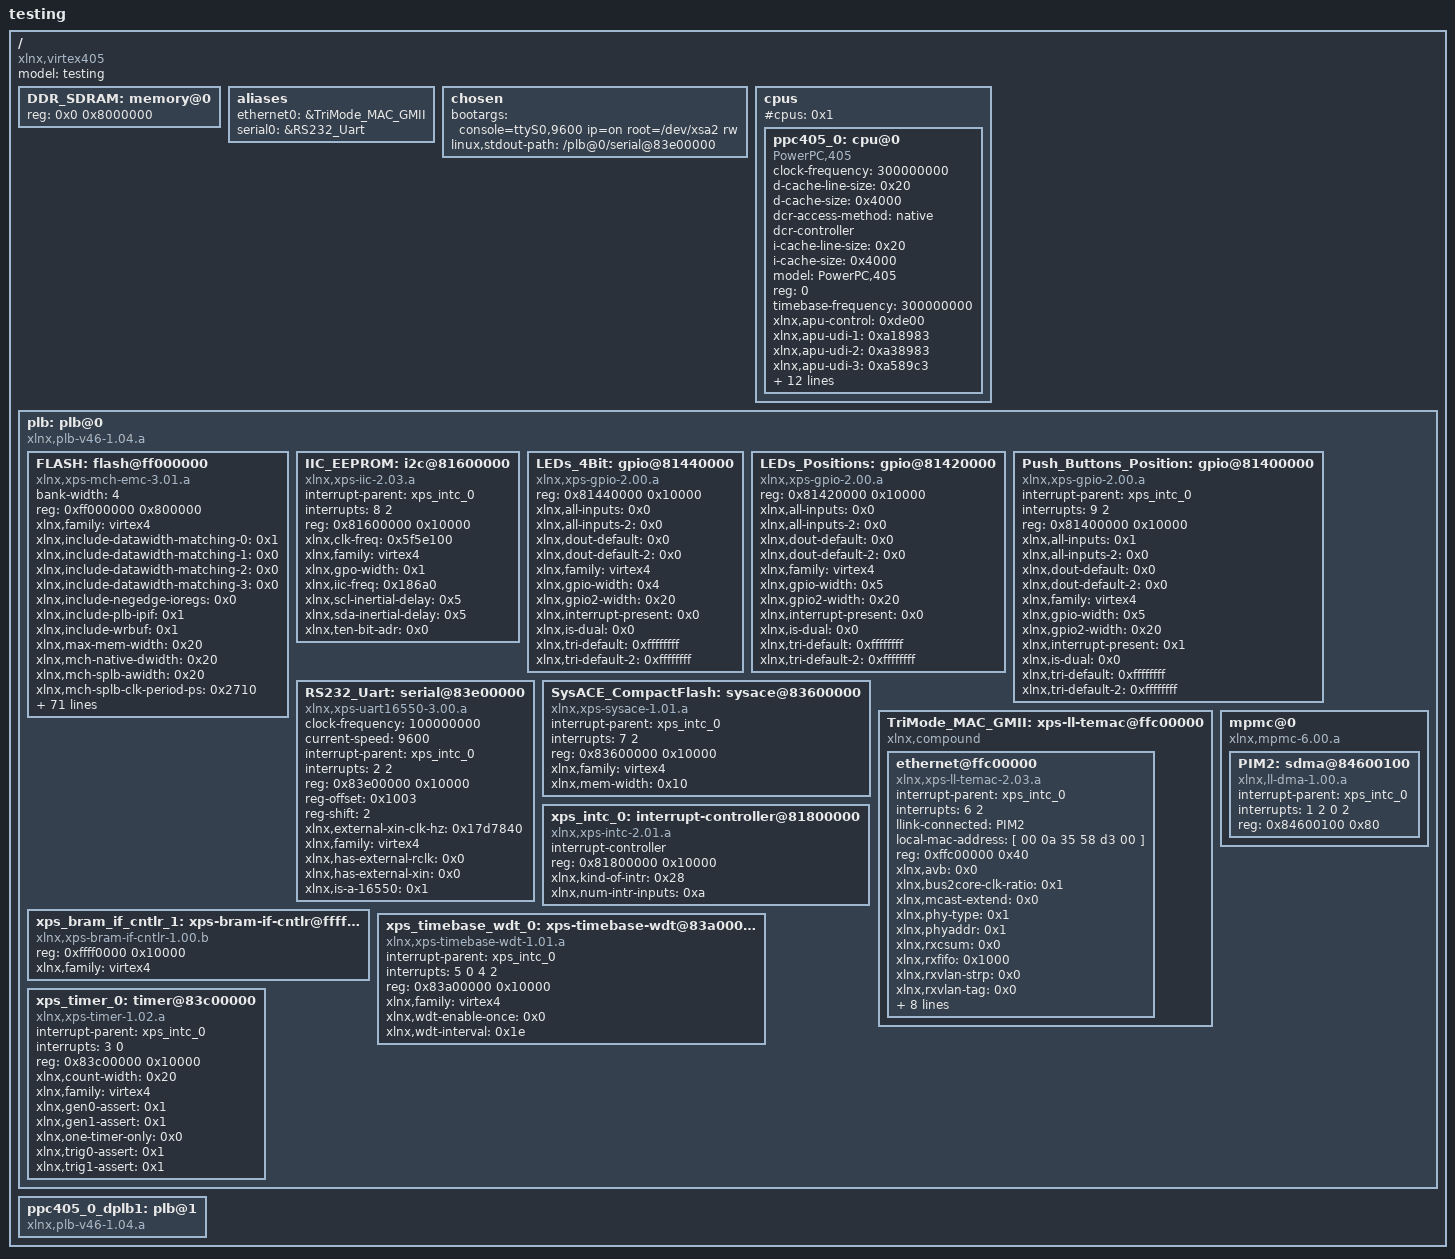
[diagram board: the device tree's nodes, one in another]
/*
 * Device Tree Generator version: 1.3
 *
 * (C) Copyright 2007-2008 Xilinx, Inc.
 * (C) Copyright 2007-2009 Michal Simek
 *
 * Michal SIMEK <monstr@monstr.eu>
 *
 * This program is free software; you can redistribute it and/or
 * modify it under the terms of the GNU General Public License as
 * published by the Free Software Foundation; either version 2 of
 * the License, or (at your option) any later version.
 *
 * This program is distributed in the hope that it will be useful,
 * but WITHOUT ANY WARRANTY; without even the implied warranty of
 * MERCHANTABILITY or FITNESS FOR A PARTICULAR PURPOSE. See the
 * GNU General Public License for more details.
 *
 * You should have received a copy of the GNU General Public License
 * along with this program; if not, write to the Free Software
 * Foundation, Inc., 59 Temple Place, Suite 330, Boston,
 * MA 02111-1307 USA
 *
 * CAUTION: This file is automatically generated by libgen.
 * Version: Xilinx EDK 12.1 EDK_MS1.53d
 *
 * XPS project directory: xilinx-ml405-ref
 */

/dts-v1/;
/ {
	#address-cells = <1>;
	#size-cells = <1>;
	compatible = "xlnx,virtex405", "xlnx,virtex";
	model = "testing";
	DDR_SDRAM: memory@0 {
		device_type = "memory";
		reg = < 0x0 0x8000000 >;
	} ;
	aliases {
		ethernet0 = &TriMode_MAC_GMII;
		serial0 = &RS232_Uart;
	} ;
	chosen {
		bootargs = "console=ttyS0,9600 ip=on root=/dev/xsa2 rw";
		linux,stdout-path = "/plb@0/serial@83e00000";
	} ;
	cpus {
		#address-cells = <1>;
		#cpus = <0x1>;
		#size-cells = <0>;
		ppc405_0: cpu@0 {
			clock-frequency = <300000000>;
			compatible = "PowerPC,405", "ibm,ppc405";
			d-cache-line-size = <0x20>;
			d-cache-size = <0x4000>;
			dcr-access-method = "native";
			dcr-controller ;
			device_type = "cpu";
			i-cache-line-size = <0x20>;
			i-cache-size = <0x4000>;
			model = "PowerPC,405";
			reg = <0>;
			timebase-frequency = <300000000>;
			xlnx,apu-control = <0xde00>;
			xlnx,apu-udi-1 = <0xa18983>;
			xlnx,apu-udi-2 = <0xa38983>;
			xlnx,apu-udi-3 = <0xa589c3>;
			xlnx,apu-udi-4 = <0xa789c3>;
			xlnx,apu-udi-5 = <0xa98c03>;
			xlnx,apu-udi-6 = <0xab8c03>;
			xlnx,apu-udi-7 = <0xad8c43>;
			xlnx,apu-udi-8 = <0xaf8c43>;
			xlnx,deterministic-mult = <0x0>;
			xlnx,disable-operand-forwarding = <0x1>;
			xlnx,fastest-plb-clock = "DPLB0";
			xlnx,generate-plb-timespecs = <0x1>;
			xlnx,mmu-enable = <0x1>;
			xlnx,pvr-high = <0x0>;
			xlnx,pvr-low = <0x0>;
		} ;
	} ;
	plb: plb@0 {
		#address-cells = <1>;
		#size-cells = <1>;
		compatible = "xlnx,plb-v46-1.04.a", "xlnx,plb-v46-1.00.a", "simple-bus";
		ranges ;
		FLASH: flash@ff000000 {
			bank-width = <4>;
			compatible = "xlnx,xps-mch-emc-3.01.a", "cfi-flash";
			reg = < 0xff000000 0x800000 >;
			xlnx,family = "virtex4";
			xlnx,include-datawidth-matching-0 = <0x1>;
			xlnx,include-datawidth-matching-1 = <0x0>;
			xlnx,include-datawidth-matching-2 = <0x0>;
			xlnx,include-datawidth-matching-3 = <0x0>;
			xlnx,include-negedge-ioregs = <0x0>;
			xlnx,include-plb-ipif = <0x1>;
			xlnx,include-wrbuf = <0x1>;
			xlnx,max-mem-width = <0x20>;
			xlnx,mch-native-dwidth = <0x20>;
			xlnx,mch-splb-awidth = <0x20>;
			xlnx,mch-splb-clk-period-ps = <0x2710>;
			xlnx,mch0-accessbuf-depth = <0x10>;
			xlnx,mch0-protocol = <0x0>;
			xlnx,mch0-rddatabuf-depth = <0x10>;
			xlnx,mch1-accessbuf-depth = <0x10>;
			xlnx,mch1-protocol = <0x0>;
			xlnx,mch1-rddatabuf-depth = <0x10>;
			xlnx,mch2-accessbuf-depth = <0x10>;
			xlnx,mch2-protocol = <0x0>;
			xlnx,mch2-rddatabuf-depth = <0x10>;
			xlnx,mch3-accessbuf-depth = <0x10>;
			xlnx,mch3-protocol = <0x0>;
			xlnx,mch3-rddatabuf-depth = <0x10>;
			xlnx,mem0-width = <0x20>;
			xlnx,mem1-width = <0x20>;
			xlnx,mem2-width = <0x20>;
			xlnx,mem3-width = <0x20>;
			xlnx,num-banks-mem = <0x1>;
			xlnx,num-channels = <0x0>;
			xlnx,pagemode-flash-0 = <0x0>;
			xlnx,pagemode-flash-1 = <0x0>;
			xlnx,pagemode-flash-2 = <0x0>;
			xlnx,pagemode-flash-3 = <0x0>;
			xlnx,priority-mode = <0x0>;
			xlnx,synch-mem-0 = <0x0>;
			xlnx,synch-mem-1 = <0x0>;
			xlnx,synch-mem-2 = <0x0>;
			xlnx,synch-mem-3 = <0x0>;
			xlnx,synch-pipedelay-0 = <0x2>;
			xlnx,synch-pipedelay-1 = <0x2>;
			xlnx,synch-pipedelay-2 = <0x2>;
			xlnx,synch-pipedelay-3 = <0x2>;
			xlnx,tavdv-ps-mem-0 = <0x1adb0>;
			xlnx,tavdv-ps-mem-1 = <0x3a98>;
			xlnx,tavdv-ps-mem-2 = <0x3a98>;
			xlnx,tavdv-ps-mem-3 = <0x3a98>;
			xlnx,tcedv-ps-mem-0 = <0x1adb0>;
			xlnx,tcedv-ps-mem-1 = <0x3a98>;
			xlnx,tcedv-ps-mem-2 = <0x3a98>;
			xlnx,tcedv-ps-mem-3 = <0x3a98>;
			xlnx,thzce-ps-mem-0 = <0x2710>;
			xlnx,thzce-ps-mem-1 = <0x1b58>;
			xlnx,thzce-ps-mem-2 = <0x1b58>;
			xlnx,thzce-ps-mem-3 = <0x1b58>;
			xlnx,thzoe-ps-mem-0 = <0x1b58>;
			xlnx,thzoe-ps-mem-1 = <0x1b58>;
			xlnx,thzoe-ps-mem-2 = <0x1b58>;
			xlnx,thzoe-ps-mem-3 = <0x1b58>;
			xlnx,tlzwe-ps-mem-0 = <0x88b8>;
			xlnx,tlzwe-ps-mem-1 = <0x0>;
			xlnx,tlzwe-ps-mem-2 = <0x0>;
			xlnx,tlzwe-ps-mem-3 = <0x0>;
			xlnx,tpacc-ps-flash-0 = <0x61a8>;
			xlnx,tpacc-ps-flash-1 = <0x61a8>;
			xlnx,tpacc-ps-flash-2 = <0x61a8>;
			xlnx,tpacc-ps-flash-3 = <0x61a8>;
			xlnx,twc-ps-mem-0 = <0xd6d8>;
			xlnx,twc-ps-mem-1 = <0x3a98>;
			xlnx,twc-ps-mem-2 = <0x3a98>;
			xlnx,twc-ps-mem-3 = <0x3a98>;
			xlnx,twp-ps-mem-0 = <0xd6d8>;
			xlnx,twp-ps-mem-1 = <0x2ee0>;
			xlnx,twp-ps-mem-2 = <0x2ee0>;
			xlnx,twp-ps-mem-3 = <0x2ee0>;
			xlnx,xcl0-linesize = <0x4>;
			xlnx,xcl0-writexfer = <0x1>;
			xlnx,xcl1-linesize = <0x4>;
			xlnx,xcl1-writexfer = <0x1>;
			xlnx,xcl2-linesize = <0x4>;
			xlnx,xcl2-writexfer = <0x1>;
			xlnx,xcl3-linesize = <0x4>;
			xlnx,xcl3-writexfer = <0x1>;
		} ;
		IIC_EEPROM: i2c@81600000 {
			compatible = "xlnx,xps-iic-2.03.a", "xlnx,xps-iic-2.00.a";
			interrupt-parent = <&xps_intc_0>;
			interrupts = < 8 2 >;
			reg = < 0x81600000 0x10000 >;
			xlnx,clk-freq = <0x5f5e100>;
			xlnx,family = "virtex4";
			xlnx,gpo-width = <0x1>;
			xlnx,iic-freq = <0x186a0>;
			xlnx,scl-inertial-delay = <0x5>;
			xlnx,sda-inertial-delay = <0x5>;
			xlnx,ten-bit-adr = <0x0>;
		} ;
		LEDs_4Bit: gpio@81440000 {
			compatible = "xlnx,xps-gpio-2.00.a", "xlnx,xps-gpio-1.00.a";
			reg = < 0x81440000 0x10000 >;
			xlnx,all-inputs = <0x0>;
			xlnx,all-inputs-2 = <0x0>;
			xlnx,dout-default = <0x0>;
			xlnx,dout-default-2 = <0x0>;
			xlnx,family = "virtex4";
			xlnx,gpio-width = <0x4>;
			xlnx,gpio2-width = <0x20>;
			xlnx,interrupt-present = <0x0>;
			xlnx,is-dual = <0x0>;
			xlnx,tri-default = <0xffffffff>;
			xlnx,tri-default-2 = <0xffffffff>;
		} ;
		LEDs_Positions: gpio@81420000 {
			compatible = "xlnx,xps-gpio-2.00.a", "xlnx,xps-gpio-1.00.a";
			reg = < 0x81420000 0x10000 >;
			xlnx,all-inputs = <0x0>;
			xlnx,all-inputs-2 = <0x0>;
			xlnx,dout-default = <0x0>;
			xlnx,dout-default-2 = <0x0>;
			xlnx,family = "virtex4";
			xlnx,gpio-width = <0x5>;
			xlnx,gpio2-width = <0x20>;
			xlnx,interrupt-present = <0x0>;
			xlnx,is-dual = <0x0>;
			xlnx,tri-default = <0xffffffff>;
			xlnx,tri-default-2 = <0xffffffff>;
		} ;
		Push_Buttons_Position: gpio@81400000 {
			compatible = "xlnx,xps-gpio-2.00.a", "xlnx,xps-gpio-1.00.a";
			interrupt-parent = <&xps_intc_0>;
			interrupts = < 9 2 >;
			reg = < 0x81400000 0x10000 >;
			xlnx,all-inputs = <0x1>;
			xlnx,all-inputs-2 = <0x0>;
			xlnx,dout-default = <0x0>;
			xlnx,dout-default-2 = <0x0>;
			xlnx,family = "virtex4";
			xlnx,gpio-width = <0x5>;
			xlnx,gpio2-width = <0x20>;
			xlnx,interrupt-present = <0x1>;
			xlnx,is-dual = <0x0>;
			xlnx,tri-default = <0xffffffff>;
			xlnx,tri-default-2 = <0xffffffff>;
		} ;
		RS232_Uart: serial@83e00000 {
			clock-frequency = <100000000>;
			compatible = "xlnx,xps-uart16550-3.00.a", "ns16550";
			current-speed = <9600>;
			device_type = "serial";
			interrupt-parent = <&xps_intc_0>;
			interrupts = < 2 2 >;
			reg = < 0x83e00000 0x10000 >;
			reg-offset = <0x1003>;
			reg-shift = <2>;
			xlnx,external-xin-clk-hz = <0x17d7840>;
			xlnx,family = "virtex4";
			xlnx,has-external-rclk = <0x0>;
			xlnx,has-external-xin = <0x0>;
			xlnx,is-a-16550 = <0x1>;
		} ;
		SysACE_CompactFlash: sysace@83600000 {
			compatible = "xlnx,xps-sysace-1.01.a", "xlnx,xps-sysace-1.00.a";
			interrupt-parent = <&xps_intc_0>;
			interrupts = < 7 2 >;
			reg = < 0x83600000 0x10000 >;
			xlnx,family = "virtex4";
			xlnx,mem-width = <0x10>;
		} ;
		TriMode_MAC_GMII: xps-ll-temac@ffc00000 {
			#address-cells = <1>;
			#size-cells = <1>;
			compatible = "xlnx,compound";
			ethernet@ffc00000 {
				compatible = "xlnx,xps-ll-temac-2.03.a", "xlnx,xps-ll-temac-1.00.a";
				device_type = "network";
				interrupt-parent = <&xps_intc_0>;
				interrupts = < 6 2 >;
				llink-connected = <&PIM2>;
				local-mac-address = [ 00 0a 35 58 d3 00 ];
				reg = < 0xffc00000 0x40 >;
				xlnx,avb = <0x0>;
				xlnx,bus2core-clk-ratio = <0x1>;
				xlnx,mcast-extend = <0x0>;
				xlnx,phy-type = <0x1>;
				xlnx,phyaddr = <0x1>;
				xlnx,rxcsum = <0x0>;
				xlnx,rxfifo = <0x1000>;
				xlnx,rxvlan-strp = <0x0>;
				xlnx,rxvlan-tag = <0x0>;
				xlnx,rxvlan-tran = <0x0>;
				xlnx,stats = <0x0>;
				xlnx,temac-type = <0x1>;
				xlnx,txcsum = <0x0>;
				xlnx,txfifo = <0x1000>;
				xlnx,txvlan-strp = <0x0>;
				xlnx,txvlan-tag = <0x0>;
				xlnx,txvlan-tran = <0x0>;
			} ;
		} ;
		mpmc@0 {
			#address-cells = <1>;
			#size-cells = <1>;
			compatible = "xlnx,mpmc-6.00.a";
			PIM2: sdma@84600100 {
				compatible = "xlnx,ll-dma-1.00.a";
				interrupt-parent = <&xps_intc_0>;
				interrupts = < 1 2 0 2 >;
				reg = < 0x84600100 0x80 >;
			} ;
		} ;
		xps_bram_if_cntlr_1: xps-bram-if-cntlr@ffff0000 {
			compatible = "xlnx,xps-bram-if-cntlr-1.00.b", "xlnx,xps-bram-if-cntlr-1.00.a";
			reg = < 0xffff0000 0x10000 >;
			xlnx,family = "virtex4";
		} ;
		xps_intc_0: interrupt-controller@81800000 {
			#interrupt-cells = <0x2>;
			compatible = "xlnx,xps-intc-2.01.a", "xlnx,xps-intc-1.00.a";
			interrupt-controller ;
			reg = < 0x81800000 0x10000 >;
			xlnx,kind-of-intr = <0x28>;
			xlnx,num-intr-inputs = <0xa>;
		} ;
		xps_timebase_wdt_0: xps-timebase-wdt@83a00000 {
			compatible = "xlnx,xps-timebase-wdt-1.01.a";
			interrupt-parent = <&xps_intc_0>;
			interrupts = < 5 0 4 2 >;
			reg = < 0x83a00000 0x10000 >;
			xlnx,family = "virtex4";
			xlnx,wdt-enable-once = <0x0>;
			xlnx,wdt-interval = <0x1e>;
		} ;
		xps_timer_0: timer@83c00000 {
			compatible = "xlnx,xps-timer-1.02.a", "xlnx,xps-timer-1.00.a";
			interrupt-parent = <&xps_intc_0>;
			interrupts = < 3 0 >;
			reg = < 0x83c00000 0x10000 >;
			xlnx,count-width = <0x20>;
			xlnx,family = "virtex4";
			xlnx,gen0-assert = <0x1>;
			xlnx,gen1-assert = <0x1>;
			xlnx,one-timer-only = <0x0>;
			xlnx,trig0-assert = <0x1>;
			xlnx,trig1-assert = <0x1>;
		} ;
	} ;
	ppc405_0_dplb1: plb@1 {
		#address-cells = <1>;
		#size-cells = <1>;
		compatible = "xlnx,plb-v46-1.04.a", "xlnx,plb-v46-1.00.a", "simple-bus";
		ranges ;
	} ;
}  ;
